# ATtiny861 register map
Vendor: Atmel
Registers are 8-bit, read-write, reset 0x0 unless marked. A register's access mark holds for its fields unless they carry their own. Offsets are from the block's base; [hi:lo] are bit positions; {n}, {i} and the like mark numbered series; <NAME> marks a mode.

## BOOT_LOAD — Bootloader
Base 0x00000057
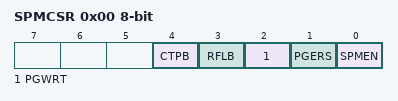
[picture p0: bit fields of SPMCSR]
0x00 SPMCSR ro — Store Program Memory Control Register
  [4] CTPB — Clear temporary page buffer
  [3] RFLB — Read fuse and lock bits
  [2] PGWRT — Page Write
  [1] PGERS — Page Erase
  [0] SPMEN — Store Program Memory Enable

## CPU — CPU Registers
Base 0x0000002A
0x00 GPIOR0 — General purpose register 0
0x01 GPIOR1 — General Purpose register 1
0x02 GPIOR2 — General Purpose IO register 2
0x16 DWDR — debugWire data register
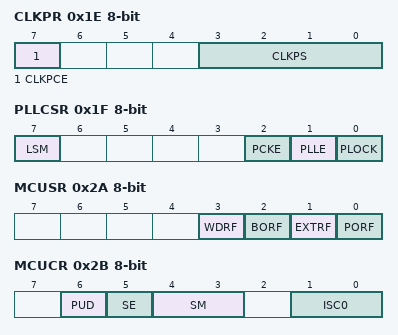
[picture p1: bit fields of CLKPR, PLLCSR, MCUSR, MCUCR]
0x1E CLKPR ro — Clock Prescale Register
  [7] CLKPCE — Clock Prescaler Change Enable
  [3:0] CLKPS — Clock Prescaler Select Bits
    0=1; 1=2; 2=4; 3=8; 4=16; 5=32; 6=64; 7=128; 8=256
0x1F PLLCSR — PLL Control and status register
  [7] LSM — Low speed mode
  [2] PCKE — PCK Enable
  [1] PLLE — PLL Enable
  [0] PLOCK — PLL Lock detector
0x27 OSCCAL ro — Oscillator Calibration Register
  [7:0] OSCCAL — Oscillator Calibration
0x2A MCUSR — MCU Status register
  [3] WDRF — Watchdog Reset Flag
  [2] BORF — Brown-out Reset Flag
  [1] EXTRF — External Reset Flag
  [0] PORF — Power-On Reset Flag
0x2B MCUCR — MCU Control Register
  [6] PUD — Pull-up Disable
  [5] SE — Sleep Enable
  [4:3] SM — Sleep Mode Select Bits
    0=IDLE; 1=ADC (ADC Noise Reduction (If Available)); 2=PDOWN (Power Down); 3=STDBY (Standby)
  [1:0] ISC0 — Interrupt Sense Control 0 bits
    0=Low Level of INTX; 1=Any Logical Change in INTX; 2=Falling Edge of INTX; 3=Rising Edge of INTX
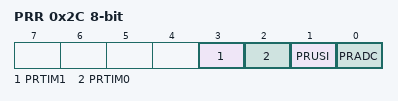
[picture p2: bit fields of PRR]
0x2C PRR — Power Reduction Register
  [3] PRTIM1 — Power Reduction Timer/Counter1
  [2] PRTIM0 — Power Reduction Timer/Counter0
  [1] PRUSI — Power Reduction USI
  [0] PRADC — Power Reduction ADC

## EEPROM
Base 0x0000003C
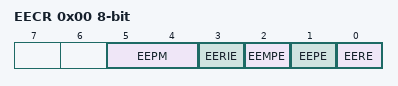
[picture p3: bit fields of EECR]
0x00 EECR — EEPROM Control Register
  [5:4] EEPM — EEPROM Programming Mode Bits
    0=Erase and Write in one operation; 1=Erase Only; 2=Write Only
  [3] EERIE — EEPROM Ready Interrupt Enable
  [2] EEMPE — EEPROM Master Write Enable
  [1] EEPE — EEPROM Write Enable
  [0] EERE — EEPROM Read Enable
0x01 EEDR — EEPROM Data Register
0x02 EEAR 16-bit (reset mask 0xFF) — EEPROM Address Register Bytes

## EXINT — External Interrupts
Base 0x00000042
0x00 PCMSK1 — Pin Change Enable Mask 1
0x01 PCMSK0 — Pin Change Enable Mask 0
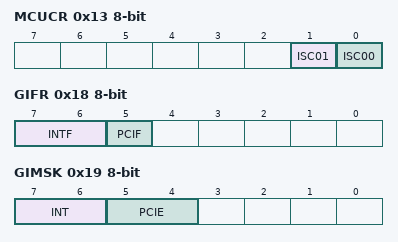
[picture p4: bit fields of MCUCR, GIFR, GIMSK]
0x13 MCUCR — MCU Control Register
  [1] ISC01 — Interrupt Sense Control 0 Bit 1
  [0] ISC00 — Interrupt Sense Control 0 Bit 0
    0=Low Level of INTX; 1=Any Logical Change of INTX
0x18 GIFR ro — General Interrupt Flag register
  [7:6] INTF — External Interrupt Flags
  [5] PCIF — Pin Change Interrupt Flag
0x19 GIMSK — General Interrupt Mask Register
  [7:6] INT — External Interrupt Request 1 Enable
  [5:4] PCIE — Pin Change Interrupt Enables

## LOCKBIT — Lockbits
Base 0x00000000
0x00 LOCKBIT — <TBD>
  [1:0] LB — Memory Lock
    0=PROG_VER_DISABLED (Further programming and verification disabled); 2=PROG_DISABLED (Further programming disabled); 3=NO_LOCK (No memory lock features enabled)

## PORTA — I/O Port
Base 0x00000039
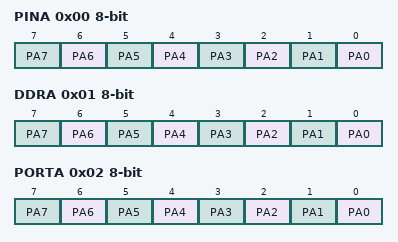
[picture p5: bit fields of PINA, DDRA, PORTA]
0x00 PINA — Port A Input Pins
  [n] PA{n} (n=0..7) — Pin A{n}
0x01 DDRA — Port A Data Direction Register
  [n] PA{n} (n=0..7) — Pin A{n}
0x02 PORTA — Port A Data Register
  [n] PA{n} (n=0..7) — Pin A{n}

## PORTB — I/O Port
Base 0x00000036
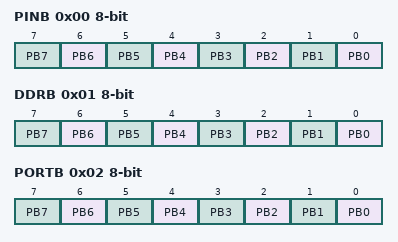
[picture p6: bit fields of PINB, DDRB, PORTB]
0x00 PINB — Port B Input Pins
  [n] PB{n} (n=0..7) — Pin B{n}
0x01 DDRB — Port B Data Direction Register
  [n] PB{n} (n=0..7) — Pin B{n}
0x02 PORTB — Port B Data Register
  [n] PB{n} (n=0..7) — Pin B{n}

## TC0 — Timer/Counter0
Base 0x00000032
0x00 OCR0B — Timer/Counter0 Output Compare Register
0x01 OCR0A — Timer/Counter0 Output Compare Register
0x02 TCNT0H — Timer/Counter0 High
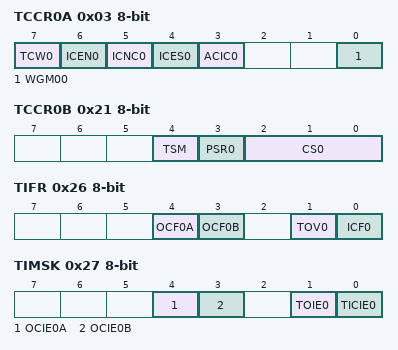
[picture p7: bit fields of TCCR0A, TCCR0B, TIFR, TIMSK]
0x03 TCCR0A — Timer/Counter Control Register A
  [7] TCW0 — Timer/Counter 0 Width
  [6] ICEN0 — Input Capture Mode Enable
  [5] ICNC0 — Input Capture Noice Canceler
  [4] ICES0 — Input Capture Edge Select
  [3] ACIC0 — Analog Comparator Input Capture Enable
  [0] WGM00 — Waveform Generation Mode
0x20 TCNT0L — Timer/Counter0 Low
0x21 TCCR0B — Timer/Counter Control Register B
  [4] TSM — Timer/Counter Synchronization Mode
  [3] PSR0 — Timer/Counter 0 Prescaler Reset
  [2:0] CS0 — Clock Select
    0=NO_CLOCK (No clock source (Timer/Counter stopped)); 1=DIRECT (Running, No Prescaling); 2=PRESCALE_8 (Running, CLK/8); 3=PRESCALE_64 (Running, CLK/64); 4=PRESCALE_256 (Running, CLK/256); 5=PRESCALE_1024 (Running, CLK/1024); 6=EXT_FALLING (Running, ExtClk Tx Falling Edge); 7=EXT_RISING (Running, ExtClk Tx Rising Edge)
0x26 TIFR ro — Timer/Counter0 Interrupt Flag register
  [4] OCF0A — Timer/Counter0 Output Compare Flag 0A
  [3] OCF0B — Timer/Counter0 Output Compare Flag 0B
  [1] TOV0 — Timer/Counter0 Overflow Flag
  [0] ICF0 — Timer/Counter0 Input Capture Flag
0x27 TIMSK — Timer/Counter Interrupt Mask Register
  [4] OCIE0A — Timer/Counter0 Output Compare Match A Interrupt Enable
  [3] OCIE0B — Timer/Counter0 Output Compare Match B Interrupt Enable
  [1] TOIE0 — Timer/Counter0 Overflow Interrupt Enable
  [0] TICIE0 — Timer/Counter0 Input Capture Interrupt Enable
